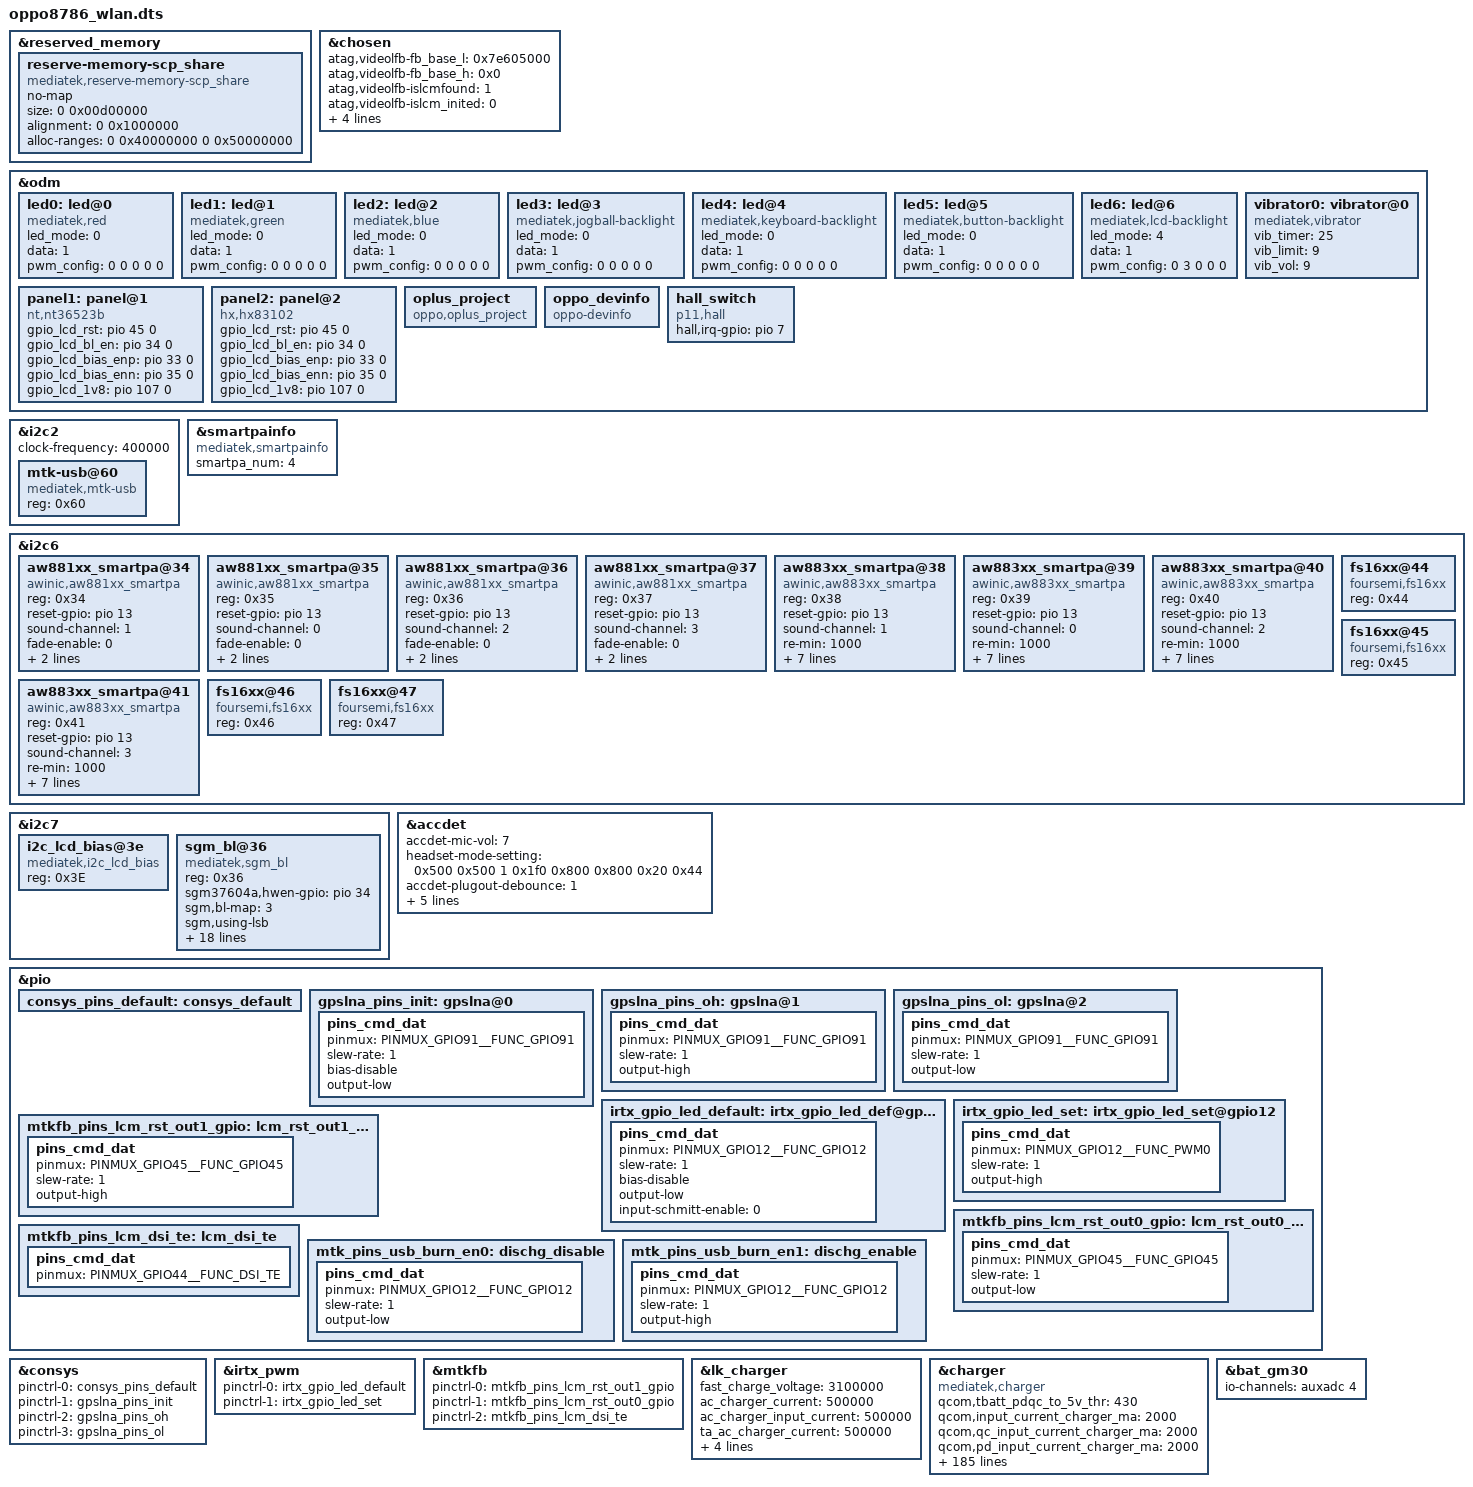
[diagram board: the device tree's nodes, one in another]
/*
 * Copyright (C) 2019 MediaTek Inc.
 *
 * This program is free software; you can redistribute it and/or modify
 * it under the terms of the GNU General Public License version 2 as
 * published by the Free Software Foundation.
 *
 * This program is distributed in the hope that it will be useful,
 * but WITHOUT ANY WARRANTY; without even the implied warranty of
 * MERCHANTABILITY or FITNESS FOR A PARTICULAR PURPOSE.
 * See http://www.gnu.org/licenses/gpl-2.0.html for more details.
 */

/dts-v1/;
/plugin/;
#include <dt-bindings/interrupt-controller/irq.h>
#include <dt-bindings/interrupt-controller/arm-gic.h>
#include <dt-bindings/pinctrl/mt6768-pinfunc.h>

&reserved_memory {
	reserve-memory-scp_share {
		compatible = "mediatek,reserve-memory-scp_share";
		no-map;
		size = <0 0x00d00000>;
		alignment = <0 0x1000000>;
		alloc-ranges = <0 0x40000000 0 0x50000000>;
	};
};

/* chosen */
&chosen {

	atag,videolfb-fb_base_l = <0x7e605000>;
	atag,videolfb-fb_base_h = <0x0>;
	atag,videolfb-islcmfound = <1>;
	atag,videolfb-islcm_inited = <0>;
	atag,videolfb-fps= <6000>;
	atag,videolfb-vramSize= <0x017e8000>;
	atag,videolfb-lcmname=
		"hx83112b_fhdp_dsi_cmd_auo_rt5081_drv";
};

&odm {
	led0:led@0 {
		compatible = "mediatek,red";
		led_mode = <0>;
		data = <1>;
		pwm_config = <0 0 0 0 0>;
	};
	led1:led@1 {
		compatible = "mediatek,green";
		led_mode = <0>;
		data = <1>;
		pwm_config = <0 0 0 0 0>;
	};
	led2:led@2 {
		compatible = "mediatek,blue";
		led_mode = <0>;
		data = <1>;
		pwm_config = <0 0 0 0 0>;
	};
	led3:led@3 {
		compatible = "mediatek,jogball-backlight";
		led_mode = <0>;
		data = <1>;
		pwm_config = <0 0 0 0 0>;
	};
	led4:led@4 {
		compatible = "mediatek,keyboard-backlight";
		led_mode = <0>;
		data = <1>;
		pwm_config = <0 0 0 0 0>;
	};
	led5:led@5 {
		compatible = "mediatek,button-backlight";
		led_mode = <0>;
		data = <1>;
		pwm_config = <0 0 0 0 0>;
	};
	led6:led@6 {
		compatible = "mediatek,lcd-backlight";
		led_mode = <4>;
		data = <1>;
		pwm_config = <0 3 0 0 0>;
	};
	vibrator0:vibrator@0 {
		compatible = "mediatek,vibrator";
		vib_timer = <25>;
		vib_limit = <9>;
		vib_vol= <9>;
	};
	panel1: panel@1 {
				compatible = "nt,nt36523b";
				gpio_lcd_rst = <&pio 45 0>;
				gpio_lcd_bl_en = <&pio 34 0>;
				gpio_lcd_bias_enp = <&pio 33 0>;
				gpio_lcd_bias_enn = <&pio 35 0>;
				gpio_lcd_1v8 = <&pio 107 0>;
				status = "okay";
    };
	panel2: panel@2 {
				compatible = "hx,hx83102";
				gpio_lcd_rst = <&pio 45 0>;
				gpio_lcd_bl_en = <&pio 34 0>;
				gpio_lcd_bias_enp = <&pio 33 0>;
				gpio_lcd_bias_enn = <&pio 35 0>;
				gpio_lcd_1v8 = <&pio 107 0>;
				status = "okay";
    };
/*Kun.Wang@BSP.Kernel.Debug, 2019/10/09, Add for oppo project & devinfo*/
	oplus_project:oplus_project {
		compatible = "oppo,oplus_project";
	};
	oppo_devinfo:oppo_devinfo {
		compatible = "oppo-devinfo";
	};

	hall_switch: hall_switch {
		compatible = "p11,hall";
		hall,irq-gpio = <&pio 7 0x00>;
	};
};

&i2c2 {
	clock-frequency = <400000>;

	mtk-usb@60 {
		compatible = "mediatek,mtk-usb";
		reg = <0x60>;
		status = "okay";
	};
};

/* smartpa info*/
&smartpainfo {
		compatible = "mediatek,smartpainfo";
		smartpa_num = <4>;
	};

&i2c6 {

/* AWINIC AW881XX Smart PA */
	aw881xx_smartpa@34 {
		compatible = "awinic,aw881xx_smartpa";
		reg = <0x34>;
		reset-gpio = <&pio 13 0>;
		/* irq-gpio = <&pio 5 0>; */
		sound-channel = <1>;
		fade-enable = <0>;
		pa-syn-enable = <0>;
		spin_data = "L R R L";
		status = "okay";
		};

	aw881xx_smartpa@35 {
		compatible = "awinic,aw881xx_smartpa";
		reg = <0x35>;
		reset-gpio = <&pio 13 0>;
		sound-channel = <0>;
		fade-enable = <0>;
		pa-syn-enable = <0>;
		spin_data = "L R R L";
		status = "okay";
		};

	aw881xx_smartpa@36 {
		compatible = "awinic,aw881xx_smartpa";
		reg = <0x36>;
		reset-gpio = <&pio 13 0>;
		sound-channel = <2>;
		fade-enable = <0>;
		pa-syn-enable = <0>;
		spin_data = "R L L R";
		status = "okay";
		};

	aw881xx_smartpa@37 {
		compatible = "awinic,aw881xx_smartpa";
		reg = <0x37>;
		reset-gpio = <&pio 13 0>;
		sound-channel = <3>;
		fade-enable = <0>;
		pa-syn-enable = <0>;
		spin_data = "R L L R";
		status = "okay";
		};
	/* AWINIC AW881XX Smart PA end*/
/* AWINIC AW883XX Smart PA */
	aw883xx_smartpa@38 {
		compatible = "awinic,aw883xx_smartpa";
		reg = <0x38>;
		reset-gpio = <&pio 13 0>;
		/* irq-gpio = <&pio 5 0>; */
		sound-channel = <1>;
		re-min = <1000>;
        re-max = <40000>;
		sync_flag = <0>;
        aw-cali-mode = "aw_attr";
		fade-enable = <0>;
		pa-syn-enable = <0>;
		spin-mode = "reg_spin";
		spin-data = "l r r l";
		status = "okay";
		};

	aw883xx_smartpa@39 {
		compatible = "awinic,aw883xx_smartpa";
		reg = <0x39>;
		reset-gpio = <&pio 13 0>;
		sound-channel = <0>;
		re-min = <1000>;
        re-max = <40000>;
        aw-cali-mode = "aw_attr";
		fade-enable = <0>;
		sync_flag = <0>;
		pa-syn-enable = <0>;
		spin-mode = "reg_spin";
		spin-data = "l r r l";
		status = "okay";
		};

	aw883xx_smartpa@40 {
		compatible = "awinic,aw883xx_smartpa";
		reg = <0x40>;
		reset-gpio = <&pio 13 0>;
		sound-channel = <2>;
		re-min = <1000>;
        re-max = <40000>;
        aw-cali-mode = "aw_attr";
		fade-enable = <0>;
		pa-syn-enable = <0>;
		sync_flag = <0>;
		spin-mode = "reg_spin";
		spin-data = "r l l r";
		status = "okay";
		};

	aw883xx_smartpa@41 {
		compatible = "awinic,aw883xx_smartpa";
		reg = <0x41>;
		reset-gpio = <&pio 13 0>;
		sound-channel = <3>;
		re-min = <1000>;
        re-max = <40000>;
        aw-cali-mode = "aw_attr";
		fade-enable = <0>;
		pa-syn-enable = <0>;
		sync_flag = <0>;
		spin-mode = "reg_spin";
		spin-data = "r l l r";
		status = "okay";
		};
	/* AWINIC AW883XX Smart PA end*/

	fs16xx@44 {
		compatible = "foursemi,fs16xx";
		reg = <0x44>;
		status = "okay";
	};

	fs16xx@45 {
		compatible = "foursemi,fs16xx";
		reg = <0x45>;
		status = "okay";
	};

	fs16xx@46 {
		compatible = "foursemi,fs16xx";
		reg = <0x46>;
		status = "okay";
	};

	fs16xx@47 {
		compatible = "foursemi,fs16xx";
		reg = <0x47>;
		status = "okay";
	};

};

&i2c7 {
        i2c_lcd_bias@3e {
            compatible = "mediatek,i2c_lcd_bias";
            reg = <0x3E>;
			status = "okay";
        };
        sgm_bl@36 {
			compatible = "mediatek,sgm_bl";
			reg = <0x36>;
			sgm37604a,hwen-gpio = <&pio 34 0>;
			/* brightness map level 1:256,2:1024,3:2048 */
			sgm,bl-map = <3>;
			sgm,using-lsb;
			sgm,ovp-level = <2>; /* 31V */
			sgm,ocp-level = <1>; /* 1.8A */
			sgm,switch-freq = <1>; /* 1000kHz(default) */
			sgm,auto-freq-high = <0x10>;
			sgm,auto-freq-low = <0x05>;
			sgm,bl-fscal-led = <0x10>; /* 17.5mA */
			sgm,bl-channel = <4>;
			sgm,turn-on-ramp = <0x09>; /* 256ms */
			sgm,turn-off-ramp = <0x09>; /* 256ms */
			sgm,pwm-trans-dim = <0>; /* 2ms */
			sgm,i2c-trans-dim = <0x07>; /* 512ms */
			sgm,pwm-mode = <0>; /* 0 pwm enable,1 PWM disable */
			sgm,map-type = <1>; /* linear */
			sgm,work-mode = <0>; /* backlight */
			sgm,flash-timeout-time = <0x05>; /* 500ms(default) */
			sh-current = <0x08>; /* 59.2mA(default) */
			sgm,efuse-config = <0x1C 0x61 0x61 0x4C 0x2C 0xC0 0x08 0x00 0x01 0xC0 0x00 0x00 0x50>;

			status = "okay";
		};
};
/* accdet start */
&accdet {
	/* accdet micbias voltage: 0x07,2.7v;0x05,2.5v;0x02,1.9v */
	accdet-mic-vol = <7>;
	headset-mode-setting = <0x500 0x500 1 0x1f0 0x800 0x800 0x20 0x44>;
	accdet-plugout-debounce = <1>;
	/*1:ACC mode, 2:low cost without in bias, 6:low cost with in bias*/
	accdet-mic-mode = <1>;
	/* eint_level_trigger: 8,LEVEL_LOW(DEF) ;4,LV_HIGH;others,LV_LOW */
	headset-eint-level-pol = <8>;
	/*0--MD_MAX--UP_MAX--DW_MAX*/
	headset-three-key-threshold = <0 80 220 400>;
	headset-three-key-threshold-CDD = <0 121 192 600>;
	/*0--MD_MAX--VOICE_MAX--UP_MAX--DW_MAX*/
	headset-four-key-threshold = <0 58 121 192 400>;
	status = "okay";
};
/* accdet end */

/* CONSYS GPIO standardization */
&pio {
	consys_pins_default: consys_default {
	};
	gpslna_pins_init: gpslna@0 {
		pins_cmd_dat {
			pinmux = <PINMUX_GPIO91__FUNC_GPIO91>;
			slew-rate = <1>;
			bias-disable;
			output-low;
		};
	};
	gpslna_pins_oh: gpslna@1 {
		pins_cmd_dat {
			pinmux = <PINMUX_GPIO91__FUNC_GPIO91>;
			slew-rate = <1>;
			output-high;
		};
	};
	gpslna_pins_ol: gpslna@2 {
		pins_cmd_dat {
			pinmux = <PINMUX_GPIO91__FUNC_GPIO91>;
			slew-rate = <1>;
			output-low;
		};
	};
};
&consys {
	pinctrl-names = "default", "gps_lna_state_init",
		"gps_lna_state_oh", "gps_lna_state_ol";
	pinctrl-0 = <&consys_pins_default>;
	pinctrl-1 = <&gpslna_pins_init>;
	pinctrl-2 = <&gpslna_pins_oh>;
	pinctrl-3 = <&gpslna_pins_ol>;
	status = "okay";
};
/* CONSYS end */

/* IRTX GPIO Start */
&irtx_pwm {
	pinctrl-names = "irtx_gpio_led_default", "irtx_gpio_led_set";
	pinctrl-0 = <&irtx_gpio_led_default>;
	pinctrl-1 = <&irtx_gpio_led_set>;
	status = "okay";
};
&pio {
	/* IRTX GPIO Settings -Start */
	/* default: GPIO0, output, high */
	irtx_gpio_led_default:irtx_gpio_led_def@gpio12 {
		pins_cmd_dat {
			pinmux = <PINMUX_GPIO12__FUNC_GPIO12>;
			slew-rate = <1>;
			bias-disable;
			output-low;
			input-schmitt-enable = <0>;
		};
	};

	irtx_gpio_led_set:irtx_gpio_led_set@gpio12 {
		pins_cmd_dat {
			pinmux = <PINMUX_GPIO12__FUNC_PWM0>;
			slew-rate = <1>;
			output-high;
		};
	};
}; /* IRTX GPIO Settings -End */

/* DISPSYS GPIO standardization */
&pio {
	mtkfb_pins_lcm_rst_out1_gpio: lcm_rst_out1_gpio {
		pins_cmd_dat {
			pinmux = <PINMUX_GPIO45__FUNC_GPIO45>;
			slew-rate = <1>;
			output-high;
		};
	};

	mtkfb_pins_lcm_rst_out0_gpio: lcm_rst_out0_gpio {
		pins_cmd_dat {
			pinmux = <PINMUX_GPIO45__FUNC_GPIO45>;
			slew-rate = <1>;
			output-low;
		};
	};

	mtkfb_pins_lcm_dsi_te: lcm_dsi_te {
		pins_cmd_dat {
			pinmux = <PINMUX_GPIO44__FUNC_DSI_TE>;
		};
	};
};

&mtkfb {
	pinctrl-names =
		"lcm_rst_out1_gpio", "lcm_rst_out0_gpio",
		"mode_te_te";
	pinctrl-0 = <&mtkfb_pins_lcm_rst_out1_gpio>;
	pinctrl-1 = <&mtkfb_pins_lcm_rst_out0_gpio>;
	pinctrl-2 = <&mtkfb_pins_lcm_dsi_te>;
	status = "okay";
};

&lk_charger{
	fast_charge_voltage = <3100000>;
	ac_charger_current = <500000>;
	ac_charger_input_current = <500000>;
	ta_ac_charger_current = <500000>;
	temp_t4_threshold = <53>;
	temp_t3_threshold = <44>;
	temp_t1_threshold = <0>;
	support_tuv_authentication;
};

&charger {
	compatible = "mediatek,charger";
	//pinctrl-names = "default", "charger_gpio_as_output_low", "charger_gpio_as_output_high", "ship_sleep", "ship_active", "shortc_active";
	//pinctrl-0 = <&charger_pins_default>;
	//pinctrl-1 = <&charger_pins_eint_output0>;
	//pinctrl-2 = <&charger_pins_eint_output1>;
	//pinctrl-3 = <&ship_sleep_gpio>;
	//pinctrl-4 = <&ship_active_gpio>;
	//pinctrl-5 = <&shortc_active_gpio>;

	//for oplus chg framework:
	qcom,tbatt_pdqc_to_5v_thr = <430>;
	qcom,input_current_charger_ma = <2000>;
	qcom,qc_input_current_charger_ma = <2000>;
	qcom,pd_input_current_charger_ma = <2000>;
	qcom,input_current_cdp_ma = <1500>;
	qcom,input_current_usb_ma = <900>;
	qcom,input_current_led_ma = <1200>;
	qcom,input_current_led_ma_forcmcc = <500>;
	qcom,input_current_camera_ma = <2000>;
	qcom,input_current_calling_ma = <2000>;
	
	qcom,input_current_led_ma_high = <1000>;
	qcom,input_current_led_ma_warm = <1500>;
	qcom,input_current_led_ma_normal = <2000>;

	qcom,led_high_bat_decidegc = <370>;
	qcom,led_warm_bat_decidegc = <350>;

	qcom,iterm_disabled = <0>;
	qcom,iterm_ma = <350>;
	qcom,recharge-mv = <115>;

	qcom,batt_capacity_mah = <7000>; /*typical capacity*/

	qcom,removed_bat_decidegc = <190>;  /* < -19C */

	qcom,cold_bat_decidegc = <0>;  /* -2C ~ 0C */
	qcom,temp_cold_vfloat_mv = <3980>;
	qcom,temp_cold_fastchg_current_ma = <0>;

	qcom,little_cold_bat_decidegc = <0>;	/* 0C ~ 5C */
	qcom,temp_little_cold_vfloat_mv = <4385>;
	qcom,temp_little_cold_fastchg_current_ma_high = <1050>;
	qcom,temp_little_cold_fastchg_current_ma_low = <1050>;
	qcom,temp_little_cold_fastchg_current_ma = <1050>;
	qcom,temp_little_cold_usbchg_current_ma_high = <550>;
	qcom,temp_little_cold_usbchg_current_ma_low = <550>;
	qcom,temp_little_cold_usbchg_current_ma = <550>;
    qcom,qc_temp_little_cold_fastchg_current_ma_high = <1050>;
    qcom,qc_temp_little_cold_fastchg_current_ma_low = <1050>;

	qcom,cool_bat_decidegc = <50>;	/* 5C ~ 12C */
	qcom,temp_cool_vfloat_mv = <4385>;
	qcom,temp_cool_fastchg_current_ma_high = <1050>;
	qcom,temp_cool_fastchg_current_ma_low = <1050>;
	qcom,temp_cool_usbchg_current_ma_high = <550>;
	qcom,temp_cool_usbchg_current_ma_low = <550>;
    qcom,qc_temp_cool_fastchg_current_ma_high = <1050>;
    qcom,qc_temp_cool_fastchg_current_ma_low = <1050>;

	qcom,little_cool_bat_decidegc = <120>;	/* 12C ~ 17C */
	qcom,temp_little_cool_vfloat_mv = <4385>;
	qcom,temp_little_cool_fastchg_current_ma = <1050>;
	qcom,temp_little_cool_usbchg_current_ma = <550>;
	qcom,temp_little_cool_fastchg_current_ma_high = <1050>;
	qcom,temp_little_cool_fastchg_current_ma_low = <1050>;
    qcom,qc_temp_little_cool_fastchg_current_ma = <1050>;

	qcom,normal_bat_decidegc = <170>;	/* 17C ~ 43C */
	qcom,temp_normal_fastchg_current_ma = <3150>;
	qcom,temp_normal_usbchg_current_ma = <550>;
	qcom,temp_normal_vfloat_mv = <4385>;
	qcom,pd_temp_normal_fastchg_current_ma = <3150>;
    qcom,qc_temp_normal_fastchg_current_ma = <3150>;

	qcom,warm_bat_decidegc = <430>;		/* 43C ~ 50C */ /*8pin Bat Vooc project need add 3 degree C*/
	qcom,temp_warm_vfloat_mv = <4135>;
	qcom,temp_warm_fastchg_current_ma = <3150>;
	qcom,temp_warm_usbchg_current_ma = <550>;
	qcom,temp_warm_fastchg_current_ma_led_on = <500>;
        qcom,qc_temp_warm_fastchg_current_ma = <3150>;

	qcom,hot_bat_decidegc = <500>;  /* > 50C */

	qcom,non_standard_vfloat_mv = <3980>;
	qcom,non_standard_fastchg_current_ma = <512>;

	qcom,short_c_bat_cv_mv = <4330>;
	qcom,short_c_bat_vfloat_mv = <3800>;
	qcom,short_c_bat_fastchg_current_ma = <512>;
	qcom,short_c_bat_vfloat_sw_limit = <3750>;

	qcom,cold_vfloat_sw_limit = <3930>;
	qcom,little_cold_vfloat_sw_limit = <4335>;
	qcom,cool_vfloat_sw_limit = <4335>;
	qcom,little_cool_vfloat_sw_limit = <4335>;
	qcom,normal_vfloat_sw_limit = <4335>;
	qcom,warm_vfloat_sw_limit = <4085>;
	qcom,non_standard_vfloat_sw_limit = <3930>;

        qcom,normal_phase1_bat_decidegc = <120>;       /* 12C ~ 16C */
        qcom,temp_normal_phase1_vfloat_mv = <4385>;
        qcom,temp_normal_phase1_fastchg_current_ma = <3150>;

        qcom,normal_phase2_bat_decidegc = <160>;       /* 16C ~ 22C */
        qcom,temp_normal_phase2_vfloat_mv = <4385>;
        qcom,temp_normal_phase2_fastchg_current_ma_high = <3150>;
        qcom,temp_normal_phase2_fastchg_current_ma_low = <3150>;

        qcom,normal_phase3_bat_decidegc = <220>;       /* 22 ~ 34C */
        qcom,temp_normal_phase3_vfloat_mv = <4385>;
        qcom,temp_normal_phase3_fastchg_current_ma_high = <3150>;
        qcom,temp_normal_phase3_fastchg_current_ma_low = <3150>;

        qcom,normal_phase4_bat_decidegc = <340>;       /* 34C ~ 38C */
        qcom,temp_normal_phase4_vfloat_mv = <4385>;
        qcom,temp_normal_phase4_fastchg_current_ma_high = <3150>;
        qcom,temp_normal_phase4_fastchg_current_ma_low = <3150>;

        qcom,normal_phase5_bat_decidegc = <380>;       /* 38C ~ 40C */
        qcom,temp_normal_phase5_vfloat_mv = <4385>;
        qcom,temp_normal_phase5_fastchg_current_ma = <3150>;

        qcom,normal_phase6_bat_decidegc = <400>;       /* 40C ~ 45C */
        qcom,temp_normal_phase6_vfloat_mv = <4385>;
        qcom,temp_normal_phase6_fastchg_current_ma = <3150>;

	qcom,max_chg_time_sec = <10800>;
	qcom,charger_hv_thr = <10000>;
	qcom,charger_recv_thr = <9700>;
	qcom,charger_lv_thr = <3400>;
	qcom,vbatt_full_thr = <4400>;
	qcom,vbatt_hv_thr = <4500>;

	qcom,vfloat_step_mv = <10>;
	qcom,non_standard_vfloat_over_sw_limit = <4000>;
	qcom,cold_vfloat_over_sw_limit = <4000>;
	qcom,little_cold_vfloat_over_sw_limit = <4390>;
	qcom,cool_vfloat_over_sw_limit = <4390>;
	qcom,little_cool_vfloat_over_sw_limit = <4390>;
	qcom,normal_vfloat_over_sw_limit = <4390>;
	qcom,warm_vfloat_over_sw_limit = <4150>;

	qcom,vbatt_power_off = <3400>;
	qcom,vbatt_soc_1 = <3410>;
	qcom,vooc_project = <0>;
	qcom,vbatt_num = <1>;

	qcom,normal_vterm_hw_inc = <150>;
	qcom,non_normal_vterm_hw_inc = <10>;

	qcom,ff1_normal_fastchg_ma = <1088>;
	qcom,ffc2_normal_fastchg_ma = <780>;/*16C~35c*/
	qcom,ffc2_temp_warm_decidegc = <350>;
	qcom,ffc2_warm_fastchg_ma = <840>;/*35C~40c*/
	qcom,ffc2_temp_high_decidegc = <400>;
	qcom,ffc2_temp_low_decidegc = <120>;
	qcom,ff1_exit_step_ma = <488>;
	qcom,ff1_warm_exit_step_ma = <418>;
	qcom,ffc2_exit_step_ma = <180>;
	qcom,ffc2_warm_exit_step_ma = <170>;

	qcom,ffc_normal_vfloat_sw_limit = <4430>;
	qcom,ffc_temp_normal_vfloat_mv = <4500>;
	qcom,ffc_normal_vfloat_over_sw_limit = <4500>;

/*EVEN gudi@BSP.CHG.Basic, 202002, modify bq2589x,termination-current*/
	qcom,default_iterm_ma = <350>;
	qcom,default_temp_normal_fastchg_current_ma = <2200>;
	qcom,default_normal_vfloat_sw_limit = <4335>;
	qcom,default_temp_normal_vfloat_mv = <4385>;
	qcom,default_normal_vfloat_over_sw_limit = <4390>;

	//for 2nd chip:
	qcom,iterm_ma_2nd = <350>;
	qcom,recharge-mv_2nd = <121>;

	qcom,temp_little_cold_vfloat_mv_2nd = <4391>;	/* 0C ~ 5C */
	qcom,temp_cool_vfloat_mv_2nd = <4391>;	/* 5C ~ 12C */
	qcom,temp_little_cool_vfloat_mv_2nd = <4391>;	/* 12C ~ 16C */
	qcom,temp_normal_vfloat_mv_2nd = <4391>;	/* 16C ~ 45C */

	qcom,little_cold_vfloat_over_sw_limit_2nd = <4395>;
	qcom,cool_vfloat_over_sw_limit_2nd = <4395>;
	qcom,little_cool_vfloat_over_sw_limit_2nd = <4395>;
	qcom,normal_vfloat_over_sw_limit_2nd = <4395>;

	qcom,default_iterm_ma_2nd = <300>;
	qcom,default_temp_normal_vfloat_mv_2nd = <4391>;
	qcom,default_normal_vfloat_over_sw_limit_2nd = <4395>;

	//for control:
	//qcom,suspend_after_full;
	qcom,check_batt_full_by_sw;
	//qcom,external_gauge;
	qcom,chg_ctrl_by_calling;
	qcom,chg_ctrl_by_lcd;
	qcom,chg_ctrl_by_camera;
	qcom,sw_vfloat_over_protect_enable;

	//for PD9V or QC9V
	qcom,vbatt_pdqc_to_5v_thr = <4335>;
	qcom,vbatt_pdqc_to_9v_thr = <4200>;
	qcom,dual_charger_support = <1>;
	qcom,slave_pct = <30>;
	qcom,slave_chg_enable_ma = <1000>;
	qcom,slave_chg_disable_ma = <300>;

	//for step charger
	qcom,step1_time = <600>;		/*10min*/
	qcom,step1_current_ma = <3400>;		/*3400ma*/
	qcom,step2_time = <600>;		/*10min*/
	qcom,step2_current_ma = <3100>;		/*3100ma*/
	qcom,step3_current_ma = <2700>;		/*2700ma*/

	//qcom,ffc_support;

	//GPIO config:
	//qcom,chargerid_switch-gpio = <&pio 97 0x00>;
	//qcom,ship-gpio = <&pio 155 0x00>;
	//qcom,shortc-gpio = <&pio 77 0x00>;

	io-channels = <&auxadc 2>, <&auxadc 3>;
	io-channel-names = "usbtemp-ch3", "usbtemp-ch4";

	qcom,dischg-gpio = <&pio 12 0x00>;
	pinctrl-names = "dischg_disable", "dischg_enable";
	pinctrl-0 = <&mtk_pins_usb_burn_en0>;
	pinctrl-1 = <&mtk_pins_usb_burn_en1>;
	status = "okay";
};

&bat_gm30 {
		io-channels = <&auxadc 4>;
		io-channel-names = "batteryID-channel";
};
&pio {
		mtk_pins_usb_burn_en0: dischg_disable{
                pins_cmd_dat {
                        pinmux = <PINMUX_GPIO12__FUNC_GPIO12>;
                        slew-rate = <1>;
                        output-low;
                };
		};

		mtk_pins_usb_burn_en1: dischg_enable{
                pins_cmd_dat {
                        pinmux = <PINMUX_GPIO12__FUNC_GPIO12>;
                        slew-rate = <1>;
                        output-high;
                };
		};
};

/* DISPSYS GPIO standardization end*/

#include "mediatek/cust.dtsi"
#include "mediatek/cust_mt6768_camera.dtsi"
#include "mediatek/nt36523_hx83102-spi.dtsi"
#include "mediatek/cust_mt6768_sar.dtsi"
#include "mediatek/sgm4151x.dtsi"
#include "mediatek/z350.dtsi"
#include "mediatek/bq2589x.dtsi"
#include "mediatek/sy6974.dtsi"
/*End of this file, DO NOT ADD ANYTHING HERE*/
